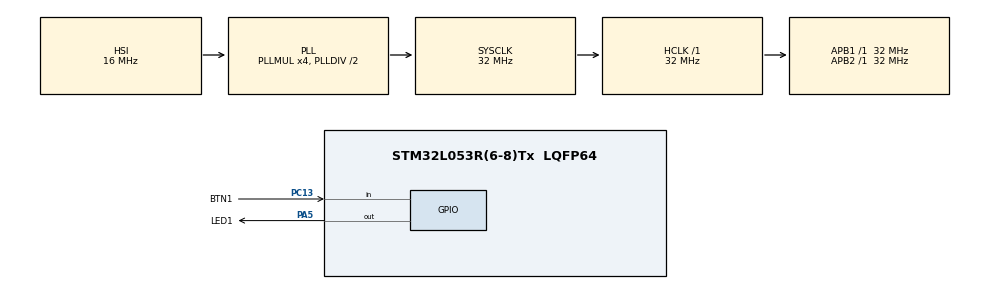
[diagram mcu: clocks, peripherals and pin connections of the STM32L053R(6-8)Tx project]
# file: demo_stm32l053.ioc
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Mcu.Family=STM32L0
Mcu.Name=STM32L053R(6-8)Tx
Mcu.Package=LQFP64
PA13.Mode=Serial_Wire
PA13.Signal=SYS_SWDIO
PA14.Mode=Serial_Wire
PA14.Signal=SYS_SWCLK
PA5.GPIO_Label=LED1
PA5.Signal=GPIO_Output
PC13.GPIO_Label=BTN1
PC13.GPIO_PuPd=GPIO_NOPULL
PC13.Signal=GPIO_Input
ProjectManager.HeapSize=0x200
ProjectManager.StackSize=0x400
ProjectManager.TargetToolchain=STM32CubeIDE
RCC.AHBFreq_Value=32000000
RCC.APB1Freq_Value=32000000
RCC.APB1TimFreq_Value=32000000
RCC.APB2Freq_Value=32000000
RCC.APB2TimFreq_Value=32000000
RCC.HCLKFreq_Value=32000000
RCC.HSE_VALUE=8000000
RCC.HSI16_VALUE=16000000
RCC.HSI48_VALUE=48000000
RCC.HSI_VALUE=16000000
RCC.LSE_VALUE=32768
RCC.MSI_VALUE=2097000
RCC.PLLMUL=RCC_PLLMUL_4
RCC.SYSCLKFreq_VALUE=32000000
RCC.SYSCLKSource=RCC_SYSCLKSOURCE_PLLCLK
RCC.VCOOutputFreq_Value=64000000
board=NUCLEO-L053R8

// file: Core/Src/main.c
/* USER CODE BEGIN Header */
/**
  ******************************************************************************
  * @file           : main.c
  * @brief          : Main program body
  ******************************************************************************
  * @attention
  *
  * <h2><center>&copy; Copyright (c) 2020 STMicroelectronics.
  * All rights reserved.</center></h2>
  *
  * This software component is licensed by ST under BSD 3-Clause license,
  * the "License"; You may not use this file except in compliance with the
  * License. You may obtain a copy of the License at:
  *                        opensource.org/licenses/BSD-3-Clause
  *
  ******************************************************************************
  */
#include <assert.h>
/* USER CODE END Header */

#include "main.h"

/* USER CODE BEGIN Includes */
#include "drv_swtimers.h"
#include "drv_leds.h"
#include "drv_buttons.h"

/* USER CODE END Includes */

/* USER CODE BEGIN PM */
enum {
	TIMER_LED_1,
	TIMER_BTN_1,
	TIMER_APP_1,
	TIMER_DELAY,
	TIMERS_NUM
};

enum {
	LED_1,
	LEDS_NUM
};

enum {
	BTN_1,
	BTNS_NUM
};

enum {
	GPIO_BTN1,
	GPIO_LED1,
	GPIO_NUM
};

/* USER CODE END PM */

void SystemClock_Config(void);
static void MX_GPIO_Init(void);
/* USER CODE BEGIN PFP */

void ISR_SysTick_Handler_cb(void);

static void hw_timer_isr_enable(void * hw_timer_p);
static void hw_timer_isr_disable(void * hw_timer_p);
static void hw_gpio_write(void * hw_gpio_p, uint32_t pin_idx, uint8_t pin_state);
static void hw_gpio_toggle(void * hw_gpio_p, uint32_t pin_idx);
static bool hw_gpio_read(void * hw_gpio_p, uint32_t pin_idx);

static void app_led_all_test_blink(void);
static void app_timer_handler(uint32_t timer_idx, void * arg_1_p, void * arg_2_p);
static void app_button_handler(uint32_t button_idx, buttons_event_t event, void * arg_p);

/* USER CODE END PFP */

/* USER CODE BEGIN 0 */

//------------------------------------------------------------------------------
// Software timers driver instance
//------------------------------------------------------------------------------
static swtimers_t timers_inst;
static swtimers_timer_t timers_table[TIMERS_NUM];

//------------------------------------------------------------------------------
// Hardware timer interface
//------------------------------------------------------------------------------
static const swtimers_hw_interface_t timers_hw_itf = {
    .hw_timer_p = NULL,
    .isr_enable_cb = hw_timer_isr_enable,
    .isr_disable_cb = hw_timer_isr_disable,
    .hw_start_cb = NULL,
    .hw_stop_cb = NULL,
    .hw_is_started_cb = NULL,
    .tick_ms = 1,
};

//------------------------------------------------------------------------------
// LEDs driver instance
//------------------------------------------------------------------------------
static leds_t leds_inst;
static leds_led_t leds_table[LEDS_NUM];

//------------------------------------------------------------------------------
// Hardware GPIO interface for LEDs driver
//------------------------------------------------------------------------------
static const leds_hw_interface_t leds_hw_itf = {
    .hw_gpio_p = NULL,
    .gpio_write = hw_gpio_write,
	.gpio_toggle = hw_gpio_toggle,
};

//------------------------------------------------------------------------------
// Buttons driver instance
//------------------------------------------------------------------------------
static buttons_t buttons_inst;
static buttons_button_t buttons_table[BTNS_NUM];

static const buttons_time_settings_t buttons_time_settings = {
	.bouncing_ms = 50,
	.double_click_ms = 500,
	.hold_ms = 3000,
};

//------------------------------------------------------------------------------
// Hardware GPIO interface for Buttons driver
//------------------------------------------------------------------------------
static const buttons_hw_interface_t buttons_hw_itf = {
    .hw_gpio_p = NULL,
    .isr_enable_cb = NULL,
    .isr_disable_cb = NULL,
    .gpio_read = hw_gpio_read,
};

//------------------------------------------------------------------------------
//------------------------------------------------------------------------------
void __assert_func (const char * file, int line, const char * func, const char * expr)
{
	(void)file;
	(void)line;
	(void)func;
	(void)expr;

	while(1) {
	}
}

//------------------------------------------------------------------------------
//------------------------------------------------------------------------------
void ISR_SysTick_Handler_cb(void)
{
    swtimers_isr(&timers_inst);
}

//------------------------------------------------------------------------------
//------------------------------------------------------------------------------
static void hw_timer_isr_enable(void * hw_timer_p)
{
    (void)hw_timer_p;

    HAL_ResumeTick();
}

//------------------------------------------------------------------------------
//------------------------------------------------------------------------------
static void hw_timer_isr_disable(void * hw_timer_p)
{
    (void)hw_timer_p;

    HAL_SuspendTick();
}

//------------------------------------------------------------------------------
//------------------------------------------------------------------------------
static void delay_ms(uint32_t ms)
{
	swtimers_start(&timers_inst, TIMER_DELAY, ms, SWTIMERS_MODE_SINGLE_FROM_ISR, NULL, NULL, NULL);
	while (swtimers_is_run(&timers_inst, TIMER_DELAY, NULL) == true) {
	}
}

//------------------------------------------------------------------------------
//------------------------------------------------------------------------------
static void hw_gpio_write(void * hw_gpio_p, uint32_t pin_idx, uint8_t pin_state)
{
	(void)hw_gpio_p;

	if (pin_idx == GPIO_LED1) {
	    HAL_GPIO_WritePin(LED1_GPIO_Port, LED1_Pin, pin_state);
	}
}

//------------------------------------------------------------------------------
//------------------------------------------------------------------------------
static void hw_gpio_toggle(void * hw_gpio_p, uint32_t pin_idx)
{
	(void)hw_gpio_p;

	if (pin_idx == GPIO_LED1) {
        HAL_GPIO_TogglePin(LED1_GPIO_Port, LED1_Pin);
	}
}

//------------------------------------------------------------------------------
//------------------------------------------------------------------------------
static bool hw_gpio_read(void * hw_gpio_p, uint32_t pin_idx)
{
	(void)hw_gpio_p;

	if (pin_idx == GPIO_BTN1) {
		GPIO_PinState pin_state = HAL_GPIO_ReadPin(BTN1_GPIO_Port, BTN1_Pin);
		return (pin_state == GPIO_PIN_SET);
	}

	return false;
}

//------------------------------------------------------------------------------
//------------------------------------------------------------------------------
static void app_led_all_test_blink(void)
{
	delay_ms(100);
	HAL_GPIO_WritePin(LED1_GPIO_Port, LED1_Pin, GPIO_PIN_SET);
    delay_ms(100);
    HAL_GPIO_WritePin(LED1_GPIO_Port, LED1_Pin, GPIO_PIN_RESET);
	delay_ms(100);
	HAL_GPIO_WritePin(LED1_GPIO_Port, LED1_Pin, GPIO_PIN_SET);
    delay_ms(100);
    HAL_GPIO_WritePin(LED1_GPIO_Port, LED1_Pin, GPIO_PIN_RESET);
    delay_ms(100);
}

//------------------------------------------------------------------------------
//------------------------------------------------------------------------------
static void app_timer_handler(uint32_t timer_idx, void * arg_1_p, void * arg_2_p)
{
    (void)timer_idx;
    (void)arg_1_p;
    (void)arg_2_p;

    leds_blink(&leds_inst, LED_1, 3, 50, 100, 0);
}

//------------------------------------------------------------------------------
//------------------------------------------------------------------------------
static void app_button_handler(uint32_t button_idx, buttons_event_t event, void * arg_p)
{
	(void)arg_p;

	if (button_idx == BTN_1) {

		// Stop app timer and blinking
		swtimers_stop(&timers_inst, TIMER_APP_1);
		leds_off(&leds_inst, LED_1);

		// Indicate button event
		if (event & BUTTONS_PRESSED) {
			leds_switch_on(&leds_inst, LED_1);
		}

		if (event & BUTTONS_RELEASED) {
			leds_switch_off(&leds_inst, LED_1);
		}

		if (event & BUTTONS_HOLD) {
			// Blink twice for 500 ms in 1s
			leds_blink_ext(&leds_inst, LED_1, 2, 500, 100, 0, 1000, false);
		}

		if (event & BUTTONS_DOUBLE) {
			// Blink twice for 100 ms in 1s
			leds_blink_ext(&leds_inst, LED_1, 2, 100, 100, 0, 1000, false);
		}
	}
}

/* USER CODE END 0 */

int main(void)
{
  /* USER CODE BEGIN 1 */
  // Run tests
  int32_t res = swtimers_tests();
  assert(res == 0);
  /* USER CODE END 1 */

  /* MCU Configuration--------------------------------------------------------*/

  /* Reset of all peripherals, Initializes the Flash interface and the Systick. */
  HAL_Init();

  /* Configure the system clock */
  SystemClock_Config();

  /* Initialize all configured peripherals */
  MX_GPIO_Init();
  /* USER CODE BEGIN 2 */

  // Init software timers driver
  swtimers_init(&timers_inst, &timers_hw_itf, TIMERS_NUM, timers_table);

  // Init LEDs driver
  leds_init(&leds_inst, &leds_hw_itf, LEDS_NUM, leds_table, &timers_inst);
  leds_set_pin(&leds_inst, LED_1, GPIO_LED1, TIMER_LED_1, true);

  // Init Buttons driver
  buttons_init(&buttons_inst, &buttons_hw_itf, BTNS_NUM, buttons_table, &timers_inst);
  buttons_configure(&buttons_inst, BTN_1, GPIO_BTN1, TIMER_BTN_1, true, BUTTONS_CHECK_IN_POLLING,
		  &buttons_time_settings, app_button_handler, NULL);

  /* USER CODE END 2 */

  /* Infinite loop */
  /* USER CODE BEGIN WHILE */

  // Initial blink
  app_led_all_test_blink();

  // Run app timer
  swtimers_start(&timers_inst, TIMER_APP_1, 3000, SWTIMERS_MODE_PERIODIC_FROM_LOOP, app_timer_handler, NULL, NULL);

  while (1) {
      // Driver routines
      swtimers_task(&timers_inst);
      buttons_task(&buttons_inst);

      delay_ms(5);

    /* USER CODE END WHILE */

  }
}

void SystemClock_Config(void)
{
  RCC_OscInitTypeDef RCC_OscInitStruct = {0};
  RCC_ClkInitTypeDef RCC_ClkInitStruct = {0};

  /** Configure the main internal regulator output voltage
  */
  __HAL_PWR_VOLTAGESCALING_CONFIG(PWR_REGULATOR_VOLTAGE_SCALE1);
  /** Initializes the CPU, AHB and APB busses clocks
  */
  RCC_OscInitStruct.OscillatorType = RCC_OSCILLATORTYPE_HSI;
  RCC_OscInitStruct.HSIState = RCC_HSI_ON;
  RCC_OscInitStruct.HSICalibrationValue = RCC_HSICALIBRATION_DEFAULT;
  RCC_OscInitStruct.PLL.PLLState = RCC_PLL_ON;
  RCC_OscInitStruct.PLL.PLLSource = RCC_PLLSOURCE_HSI;
  RCC_OscInitStruct.PLL.PLLMUL = RCC_PLLMUL_4;
  RCC_OscInitStruct.PLL.PLLDIV = RCC_PLLDIV_2;
  if (HAL_RCC_OscConfig(&RCC_OscInitStruct) != HAL_OK)
  {
    Error_Handler();
  }
  /** Initializes the CPU, AHB and APB busses clocks
  */
  RCC_ClkInitStruct.ClockType = RCC_CLOCKTYPE_HCLK|RCC_CLOCKTYPE_SYSCLK
                              |RCC_CLOCKTYPE_PCLK1|RCC_CLOCKTYPE_PCLK2;
  RCC_ClkInitStruct.SYSCLKSource = RCC_SYSCLKSOURCE_PLLCLK;
  RCC_ClkInitStruct.AHBCLKDivider = RCC_SYSCLK_DIV1;
  RCC_ClkInitStruct.APB1CLKDivider = RCC_HCLK_DIV1;
  RCC_ClkInitStruct.APB2CLKDivider = RCC_HCLK_DIV1;

  if (HAL_RCC_ClockConfig(&RCC_ClkInitStruct, FLASH_LATENCY_1) != HAL_OK)
  {
    Error_Handler();
  }
}

static void MX_GPIO_Init(void)
{
  GPIO_InitTypeDef GPIO_InitStruct = {0};

  /* GPIO Ports Clock Enable */
  __HAL_RCC_GPIOC_CLK_ENABLE();
  __HAL_RCC_GPIOA_CLK_ENABLE();

  /*Configure GPIO pin Output Level */
  HAL_GPIO_WritePin(LED1_GPIO_Port, LED1_Pin, GPIO_PIN_RESET);

  /*Configure GPIO pin : BTN1_Pin */
  GPIO_InitStruct.Pin = BTN1_Pin;
  GPIO_InitStruct.Mode = GPIO_MODE_INPUT;
  GPIO_InitStruct.Pull = GPIO_NOPULL;
  HAL_GPIO_Init(BTN1_GPIO_Port, &GPIO_InitStruct);

  /*Configure GPIO pin : LED1_Pin */
  GPIO_InitStruct.Pin = LED1_Pin;
  GPIO_InitStruct.Mode = GPIO_MODE_OUTPUT_PP;
  GPIO_InitStruct.Pull = GPIO_NOPULL;
  GPIO_InitStruct.Speed = GPIO_SPEED_FREQ_LOW;
  HAL_GPIO_Init(LED1_GPIO_Port, &GPIO_InitStruct);

}

void Error_Handler(void)
{
}

/************************ (C) COPYRIGHT STMicroelectronics *****END OF FILE****/
